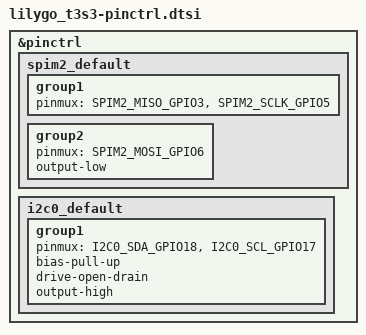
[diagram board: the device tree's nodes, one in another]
/*
 * SPDX-License-Identifier: MIT
 * LilyGo T3S3 v1.x — Pin Control Definitions
 *
 * Pin mapping (from LilyGo LoRa Series docs / MeshCore variants/lilygo_t3s3):
 *   LoRa SPI2:  SCLK=GPIO5, MOSI=GPIO6, MISO=GPIO3, NSS=GPIO7
 *   I2C0:       SDA=GPIO18, SCL=GPIO17  (SSD1306 OLED + sensors)
 *   Console:    USB Serial/JTAG (native ESP32-S3 USB, shared with USB OTG)
 *
 * NSS and reset are handled via cs-gpios / reset-gpios in the overlay,
 * not in pinctrl.
 */

#include <zephyr/dt-bindings/pinctrl/esp-pinctrl-common.h>
#include <zephyr/dt-bindings/pinctrl/esp32s3-pinctrl.h>
#include <zephyr/dt-bindings/pinctrl/esp32s3-gpio-sigmap.h>

&pinctrl {
	/* SPI2 — LoRa SX1262 (CS handled via cs-gpios, not pinctrl) */
	spim2_default: spim2_default {
		group1 {
			pinmux = <SPIM2_MISO_GPIO3>,
				 <SPIM2_SCLK_GPIO5>;
		};
		group2 {
			pinmux = <SPIM2_MOSI_GPIO6>;
			output-low;
		};
	};

	/* I2C0 — SSD1306 OLED display + optional I2C sensors */
	i2c0_default: i2c0_default {
		group1 {
			pinmux = <I2C0_SDA_GPIO18>,
				 <I2C0_SCL_GPIO17>;
			bias-pull-up;
			drive-open-drain;
			output-high;
		};
	};
};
